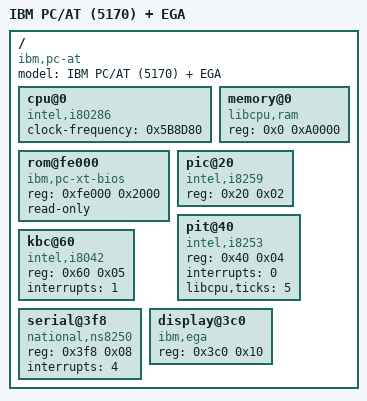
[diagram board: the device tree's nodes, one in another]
/dts-v1/;

/* IBM PC/AT-class machine with an Enhanced Graphics Adapter. The EGA exposes indexed register
   groups at 0x3C0-0x3CF (attribute controller, sequencer, graphics controller, misc output) plus
   a colour CRTC at 0x3D4/0x3D5; its planar framebuffer is at 0xA0000 and the colour-text page at
   0xB8000. Only the display node differs from the other variants. */

/ {
    model = "IBM PC/AT (5170) + EGA";
    compatible = "ibm,pc-at", "ibm,5170";
    #address-cells = <1>;
    #size-cells = <1>;

    cpu@0 {
        device_type = "cpu";
        compatible = "intel,i80286";
        clock-frequency = <0x5B8D80>;   /* 6 MHz */
    };

    memory@0 {
        device_type = "memory";
        compatible = "libcpu,ram";
        reg = <0x0 0xA0000>;
    };

    rom@fe000 {
        compatible = "ibm,pc-xt-bios";
        reg = <0xfe000 0x2000>;
        read-only;
    };

    pic@20 {
        compatible = "intel,i8259";
        reg = <0x20 0x02>;
    };

    pit@40 {
        compatible = "intel,i8253";
        reg = <0x40 0x04>;
        interrupts = <0>;
        libcpu,ticks = <5>;
    };

    kbc@60 {
        compatible = "intel,i8042";
        reg = <0x60 0x05>;              /* 8042 KBC: data 0x60, command/status 0x64 */
        interrupts = <1>;               /* keyboard -> IRQ1 */
    };

    serial@3f8 {
        compatible = "national,ns8250";
        reg = <0x3f8 0x08>;
        interrupts = <4>;
    };

    display@3c0 {
        compatible = "ibm,ega";
        reg = <0x3c0 0x10>;             /* attribute/sequencer/graphics + CRTC at 0x3d4 (fb A0000/B8000) */
    };
};
